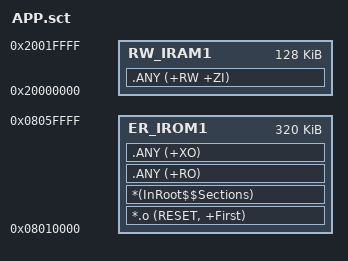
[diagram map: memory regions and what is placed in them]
; *************************************************************
; *** Scatter-Loading Description File generated by uVision ***
; *************************************************************
;
; APP partition: 0x08010000 ~ 0x0804FFFF (256 KB, matches BOOT/boot_config.h)
; The last 8 bytes (0x0804FFF8 magic / 0x0804FFFC version) are NOT linked;
; they are written by the OTA flow or Script/append_app_magic.py before flash.

LR_IROM1 0x08010000 0x00050000  {    ; load region size_region
  ER_IROM1 0x08010000 0x00050000  {  ; load address = execution address
   *.o (RESET, +First)
   *(InRoot$$Sections)
   .ANY (+RO)
   .ANY (+XO)
  }
  RW_IRAM1 0x20000000 0x00020000  {  ; RW data (128 KB main SRAM)
   .ANY (+RW +ZI)
  }
}
